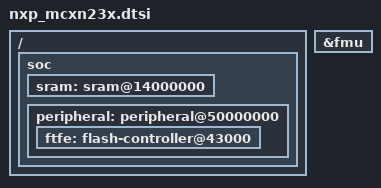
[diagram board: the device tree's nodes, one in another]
/*
 * Copyright 2024 NXP
 *
 * SPDX-License-Identifier: Apache-2.0
 */

#include <mem.h>
#include <arm/armv8-m.dtsi>

/ {
	soc {
		sram: sram@14000000 {
			ranges = <0x4000000 0x14000000 0x20000000>;
		};

		peripheral: peripheral@50000000 {
			ranges = <0x0 0x50000000 0x10000000>;

			ftfe: flash-controller@43000 {
				ranges = <0x0 0x10000000 0x4000000>;
			};
		};
	};
};

#include "nxp_mcxn23x_common.dtsi"

/*
 * Explicitly enable FMU after we include the common dtsi file,
 * which will set it to disabled.
 */
&fmu {
	status = "okay";
};
